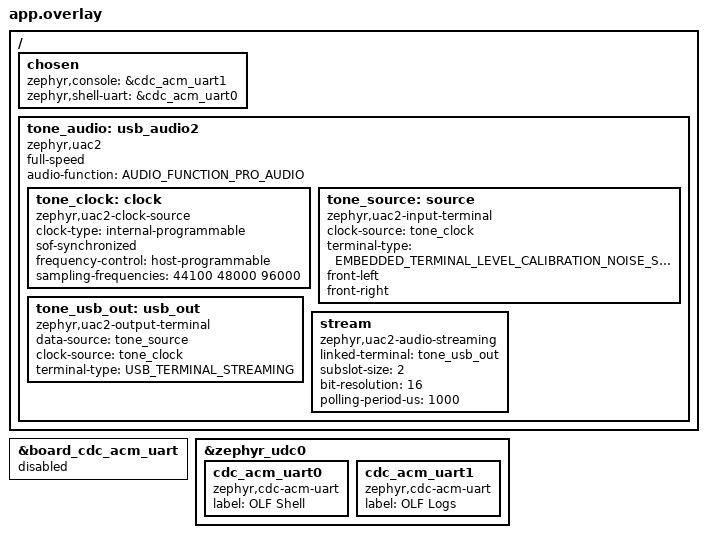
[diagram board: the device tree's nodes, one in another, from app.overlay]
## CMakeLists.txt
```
cmake_minimum_required(VERSION 3.20.0)
find_package(Zephyr REQUIRED HINTS $ENV{ZEPHYR_BASE})
project(nrf_multi_cdc_usb_next)
include(cmake/nrf52840_iso_in.cmake)
include(cmake/uac2_formats.cmake)
target_sources(app PRIVATE src/main.c src/gpio_app.c src/tone.c src/tone_usb.c)
include(cmake/tools_disk.cmake)
```

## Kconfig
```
mainmenu "OLFs Signal Generator"

source "Kconfig.zephyr"
```

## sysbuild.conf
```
# Use the original Nordic Open Bootloader; application-only sysbuild.
SB_CONFIG_BOOTLOADER_MCUBOOT=n
```

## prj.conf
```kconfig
CONFIG_SERIAL=y
CONFIG_BOOTLOADER_MCUBOOT=n
CONFIG_UART_INTERRUPT_DRIVEN=y
CONFIG_CONSOLE=y
CONFIG_UART_CONSOLE=y
CONFIG_PRINTK=y
CONFIG_SHELL=y
CONFIG_SHELL_BACKEND_SERIAL=y
CONFIG_SHELL_BACKEND_SERIAL_CHECK_DTR=y
CONFIG_LOG=y
CONFIG_LOG_DEFAULT_LEVEL=3
CONFIG_LOG_BACKEND_UART=y
CONFIG_USB_DEVICE_STACK=n
CONFIG_USB_DEVICE_STACK_NEXT=y
CONFIG_UART_LINE_CTRL=y
CONFIG_USBD_CDC_ACM_CLASS=y
CONFIG_CDC_ACM_SERIAL_INITIALIZE_AT_BOOT=n
CONFIG_MAIN_STACK_SIZE=2048
CONFIG_LOG_CMDS=y
CONFIG_LOG_RUNTIME_FILTERING=y
CONFIG_GPIO_LOG_LEVEL_DBG=y
CONFIG_GPIO=y
CONFIG_SHELL_HISTORY=y
CONFIG_SHELL_HISTORY_BUFFER=512
CONFIG_USBD_AUDIO2_CLASS=y
CONFIG_SHELL_LOG_BACKEND=n
CONFIG_SYSTEM_WORKQUEUE_STACK_SIZE=2048
CONFIG_USBD_THREAD_STACK_SIZE=2048
CONFIG_USBD_MSC_CLASS=y
```

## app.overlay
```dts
#include <dt-bindings/usb/audio.h>

/ {
    chosen {
        zephyr,console = &cdc_acm_uart1;
        zephyr,shell-uart = &cdc_acm_uart0;
    };

    tone_audio: usb_audio2 {
        compatible = "zephyr,uac2";
        status = "okay";
        full-speed;
        audio-function = <AUDIO_FUNCTION_PRO_AUDIO>;

        tone_clock: clock {
            compatible = "zephyr,uac2-clock-source";
            clock-type = "internal-programmable";
            sof-synchronized;
            frequency-control = "host-programmable";
            sampling-frequencies = <44100 48000 96000>;
        };

        tone_source: source {
            compatible = "zephyr,uac2-input-terminal";
            clock-source = <&tone_clock>;
            terminal-type = <EMBEDDED_TERMINAL_LEVEL_CALIBRATION_NOISE_SOURCE>;
            front-left;
            front-right;
        };

        tone_usb_out: usb_out {
            compatible = "zephyr,uac2-output-terminal";
            data-source = <&tone_source>;
            clock-source = <&tone_clock>;
            terminal-type = <USB_TERMINAL_STREAMING>;
        };

        stream {
            compatible = "zephyr,uac2-audio-streaming";
            linked-terminal = <&tone_usb_out>;
            /* Base alternate 1; project extension adds 24-bit alternate 2. */
            subslot-size = <2>;
            bit-resolution = <16>;
            polling-period-us = <1000>;
        };
    };
};

/* The board supplies a fourth CDC instance by default. */
&board_cdc_acm_uart {
    status = "disabled";
};

&zephyr_udc0 {
    status = "okay";

    cdc_acm_uart0: cdc_acm_uart0 {
        compatible = "zephyr,cdc-acm-uart";
        label = "OLF Shell";
    };

    cdc_acm_uart1: cdc_acm_uart1 {
        compatible = "zephyr,cdc-acm-uart";
        label = "OLF Logs";
    };
};
```

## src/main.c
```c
/* SPDX-License-Identifier: Apache-2.0 */
#include <zephyr/kernel.h>
#include <zephyr/device.h>
#include <zephyr/drivers/uart.h>
#include <zephyr/usb/usbd.h>
#include <zephyr/usb/usb_ch9.h>
#include "tone.h"
#include "tools_disk.h"
#include <zephyr/sys/util.h>
#include <zephyr/logging/log.h>
#include <errno.h>

LOG_MODULE_REGISTER(multi_cdc, LOG_LEVEL_INF);

/* USB identity for OLFs Signal Generator. */
#define DEV_VID 0x16d0
#define DEV_PID 0x1471

USBD_DEVICE_DEFINE(multi_cdc_usbd, DEVICE_DT_GET(DT_NODELABEL(zephyr_udc0)),
                   DEV_VID, DEV_PID);
USBD_DESC_LANG_DEFINE(usb_lang);
USBD_DESC_MANUFACTURER_DEFINE(usb_manufacturer, "eisenzelt.de");
USBD_DESC_PRODUCT_DEFINE(usb_product, "OLFs Signal Generator");
USBD_DESC_SERIAL_NUMBER_DEFINE(usb_serial);
USBD_DESC_CONFIG_DEFINE(fs_cfg_desc, "Audio + Shell + Logs + Tools");
USBD_CONFIGURATION_DEFINE(fs_cfg, 0, 50, &fs_cfg_desc);

static int setup_usb(void)
{
    int err;
    err = usbd_add_descriptor(&multi_cdc_usbd, &usb_lang);
    if (err) return err;
    err = usbd_add_descriptor(&multi_cdc_usbd, &usb_manufacturer);
    if (err) return err;
    err = usbd_add_descriptor(&multi_cdc_usbd, &usb_product);
    if (err) return err;
    err = usbd_add_descriptor(&multi_cdc_usbd, &usb_serial);
    if (err) return err;
    err = usbd_add_configuration(&multi_cdc_usbd, USBD_SPEED_FS, &fs_cfg);
    if (err) return err;
    /* Register two CDC ports, UAC2 audio and the read-only tools disk. */
    err = usbd_register_all_classes(&multi_cdc_usbd, USBD_SPEED_FS, 1, NULL);
    if (err) return err;
    usbd_device_set_code_triple(&multi_cdc_usbd, USBD_SPEED_FS,
                                USB_BCC_MISCELLANEOUS, 0x02, 0x01);
    err = usbd_init(&multi_cdc_usbd);
    if (err) return err;
    return usbd_enable(&multi_cdc_usbd);
}

int main(void)
{
    int err;
    err = tools_disk_init();
    if (err) {
        return err;
    }
    err = tone_usb_init();
    if (err) {
        return err;
    }

    err = setup_usb();
    if (err) {
        /* CDC console may not be operational yet: inspect return code in debugger. */
        return err;
    }
    printk("USB initialized: audio / shell / logs / tools drive\n");
    LOG_INF("USB audio generator ready: 44100/48000/96000 Hz (default %u Hz), 16/24-bit stereo", TONE_DEFAULT_SAMPLE_RATE);
    while (true) {
        k_sleep(K_SECONDS(5));
    }
    return 0;
}
```

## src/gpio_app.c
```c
/* SPDX-License-Identifier: Apache-2.0 */
#include <zephyr/drivers/gpio.h>
#include <zephyr/logging/log.h>
#include <zephyr/shell/shell.h>
#include <errno.h>
#include <string.h>

LOG_MODULE_REGISTER(gpio_app, LOG_LEVEL_DBG);

static const struct gpio_dt_spec led = GPIO_DT_SPEC_GET(DT_ALIAS(led0), gpios);

static int cmd_gpio_app_led(const struct shell *sh, size_t argc, char **argv)
{
    int err;
    int active;

    ARG_UNUSED(argc);
    if (strcmp(argv[1], "on") == 0) {
        active = 1;
    } else if (strcmp(argv[1], "off") == 0) {
        active = 0;
    } else {
        shell_error(sh, "Use: gpio_app led on|off");
        return -EINVAL;
    }

    if (!gpio_is_ready_dt(&led)) {
        LOG_ERR("LED GPIO device is not ready");
        shell_error(sh, "LED GPIO device is not ready");
        return -ENODEV;
    }

    /* Configure directly to the requested logical state, respecting active-low. */
    err = gpio_pin_configure_dt(&led, active ? GPIO_OUTPUT_ACTIVE : GPIO_OUTPUT_INACTIVE);
    if (err < 0) {
        LOG_ERR("LED configuration failed: %d", err);
        shell_error(sh, "LED configuration failed: %d", err);
        return err;
    }

    LOG_DBG("%s pin %u: LED %s (logical %d)",
            led.port->name, led.pin, active ? "on" : "off", active);
    shell_print(sh, "LED %s", active ? "on" : "off");
    return 0;
}

SHELL_STATIC_SUBCMD_SET_CREATE(gpio_app_commands,
    SHELL_CMD_ARG(led, NULL, "Set green LED: on|off", cmd_gpio_app_led, 2, 0),
    SHELL_SUBCMD_SET_END
);

SHELL_CMD_REGISTER(gpio_app, &gpio_app_commands, "Application GPIO controls", NULL);
```

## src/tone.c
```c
/* SPDX-License-Identifier: Apache-2.0 */
#include "tone.h"

static const int32_t sine_table[1025] = {
    0, 51472, 102941, 154407, 205867, 257319, 308761, 360192,
    411609, 463011, 514396, 565761, 617104, 668425, 719720, 770988,
    822227, 873435, 924611, 975751, 1026855, 1077920, 1128945, 1179927,
    1230864, 1281756, 1332599, 1383391, 1434132, 1484819, 1535450, 1586023,
    1636536, 1686988, 1737376, 1787699, 1837954, 1888140, 1938256, 1988298,
    2038265, 2088156, 2137968, 2187699, 2237349, 2286913, 2336392, 2385783,
    2435084, 2484293, 2533409, 2582430, 2631353, 2680177, 2728900, 2777521,
    2826037, 2874446, 2922747, 2970939, 3019018, 3066984, 3114834, 3162567,
    3210181, 3257674, 3305044, 3352290, 3399410, 3446402, 3493264, 3539994,
    3586592, 3633054, 3679379, 3725566, 3771613, 3817517, 3863278, 3908894,
    3954362, 3999681, 4044850, 4089867, 4134729, 4179436, 4223986, 4268376,
    4312606, 4356673, 4400577, 4444314, 4487885, 4531286, 4574517, 4617576,
    4660460, 4703170, 4745702, 4788055, 4830229, 4872220, 4914028, 4955651,
    4997087, 5038336, 5079394, 5120261, 5160936, 5201416, 5241701, 5281788,
    5321676, 5361364, 5400850, 5440132, 5479210, 5518082, 5556746, 5595200,
    5633444, 5671476, 5709294, 5746898, 5784285, 5821454, 5858404, 5895133,
    5931641, 5967925, 6003985, 6039818, 6075424, 6110801, 6145949, 6180865,
    6215548, 6249997, 6284211, 6318188, 6351927, 6385428, 6418687, 6451706,
    6484481, 6517012, 6549298, 6581337, 6613128, 6644671, 6675963, 6707004,
    6737792, 6768327, 6798607, 6828631, 6858398, 6887906, 6917156, 6946144,
    6974872, 7003337, 7031538, 7059474, 7087145, 7114548, 7141684, 7168551,
    7195148, 7221474, 7247529, 7273310, 7298818, 7324051, 7349008, 7373688,
    7398091, 7422215, 7446060, 7469624, 7492908, 7515909, 7538627, 7561061,
    7583211, 7605075, 7626653, 7647944, 7668946, 7689660, 7710085, 7730219,
    7750062, 7769614, 7788873, 7807838, 7826510, 7844887, 7862969, 7880754,
    7898243, 7915435, 7932328, 7948923, 7965219, 7981214, 7996910, 8012304,
    8027396, 8042187, 8056674, 8070858, 8084739, 8098315, 8111586, 8124551,
    8137211, 8149564, 8161611, 8173350, 8184782, 8195905, 8206720, 8217226,
    8227422, 8237309, 8246886, 8256152, 8265107, 8273751, 8282084, 8290104,
    8297813, 8305209, 8312293, 8319063, 8325521, 8331665, 8337495, 8343011,
    8348214, 8353102, 8357675, 8361934, 8365878, 8369507, 8372821, 8375819,
    8378503, 8380870, 8382923, 8384659, 8386081, 8387186, 8387975, 8388449,
    8388607, 8388449, 8387975, 8387186, 8386081, 8384659, 8382923, 8380870,
    8378503, 8375819, 8372821, 8369507, 8365878, 8361934, 8357675, 8353102,
    8348214, 8343011, 8337495, 8331665, 8325521, 8319063, 8312293, 8305209,
    8297813, 8290104, 8282084, 8273751, 8265107, 8256152, 8246886, 8237309,
    8227422, 8217226, 8206720, 8195905, 8184782, 8173350, 8161611, 8149564,
    8137211, 8124551, 8111586, 8098315, 8084739, 8070858, 8056674, 8042187,
    8027396, 8012304, 7996910, 7981214, 7965219, 7948923, 7932328, 7915435,
    7898243, 7880754, 7862969, 7844887, 7826510, 7807838, 7788873, 7769614,
    7750062, 7730219, 7710085, 7689660, 7668946, 7647944, 7626653, 7605075,
    7583211, 7561061, 7538627, 7515909, 7492908, 7469624, 7446060, 7422215,
    7398091, 7373688, 7349008, 7324051, 7298818, 7273310, 7247529, 7221474,
    7195148, 7168551, 7141684, 7114548, 7087145, 7059474, 7031538, 7003337,
    6974872, 6946144, 6917156, 6887906, 6858398, 6828631, 6798607, 6768327,
    6737792, 6707004, 6675963, 6644671, 6613128, 6581337, 6549298, 6517012,
    6484481, 6451706, 6418687, 6385428, 6351927, 6318188, 6284211, 6249997,
    6215548, 6180865, 6145949, 6110801, 6075424, 6039818, 6003985, 5967925,
    5931641, 5895133, 5858404, 5821454, 5784285, 5746898, 5709294, 5671476,
    5633444, 5595200, 5556746, 5518082, 5479210, 5440132, 5400850, 5361364,
    5321676, 5281788, 5241701, 5201416, 5160936, 5120261, 5079394, 5038336,
    4997087, 4955651, 4914028, 4872220, 4830229, 4788055, 4745702, 4703170,
    4660460, 4617576, 4574517, 4531286, 4487885, 4444314, 4400577, 4356673,
    4312606, 4268376, 4223986, 4179436, 4134729, 4089867, 4044850, 3999681,
    3954362, 3908894, 3863278, 3817517, 3771613, 3725566, 3679379, 3633054,
    3586592, 3539994, 3493264, 3446402, 3399410, 3352290, 3305044, 3257674,
    3210181, 3162567, 3114834, 3066984, 3019018, 2970939, 2922747, 2874446,
    2826037, 2777521, 2728900, 2680177, 2631353, 2582430, 2533409, 2484293,
    2435084, 2385783, 2336392, 2286913, 2237349, 2187699, 2137968, 2088156,
    2038265, 1988298, 1938256, 1888140, 1837954, 1787699, 1737376, 1686988,
    1636536, 1586023, 1535450, 1484819, 1434132, 1383391, 1332599, 1281756,
    1230864, 1179927, 1128945, 1077920, 1026855, 975751, 924611, 873435,
    822227, 770988, 719720, 668425, 617104, 565761, 514396, 463011,
    411609, 360192, 308761, 257319, 205867, 154407, 102941, 51472,
    0, -51472, -102941, -154407, -205867, -257319, -308761, -360192,
    -411609, -463011, -514396, -565761, -617104, -668425, -719720, -770988,
    -822227, -873435, -924611, -975751, -1026855, -1077920, -1128945, -1179927,
    -1230864, -1281756, -1332599, -1383391, -1434132, -1484819, -1535450, -1586023,
    -1636536, -1686988, -1737376, -1787699, -1837954, -1888140, -1938256, -1988298,
    -2038265, -2088156, -2137968, -2187699, -2237349, -2286913, -2336392, -2385783,
    -2435084, -2484293, -2533409, -2582430, -2631353, -2680177, -2728900, -2777521,
    -2826037, -2874446, -2922747, -2970939, -3019018, -3066984, -3114834, -3162567,
    -3210181, -3257674, -3305044, -3352290, -3399410, -3446402, -3493264, -3539994,
    -3586592, -3633054, -3679379, -3725566, -3771613, -3817517, -3863278, -3908894,
    -3954362, -3999681, -4044850, -4089867, -4134729, -4179436, -4223986, -4268376,
    -4312606, -4356673, -4400577, -4444314, -4487885, -4531286, -4574517, -4617576,
    -4660460, -4703170, -4745702, -4788055, -4830229, -4872220, -4914028, -4955651,
    -4997087, -5038336, -5079394, -5120261, -5160936, -5201416, -5241701, -5281788,
    -5321676, -5361364, -5400850, -5440132, -5479210, -5518082, -5556746, -5595200,
    -5633444, -5671476, -5709294, -5746898, -5784285, -5821454, -5858404, -5895133,
    -5931641, -5967925, -6003985, -6039818, -6075424, -6110801, -6145949, -6180865,
    -6215548, -6249997, -6284211, -6318188, -6351927, -6385428, -6418687, -6451706,
    -6484481, -6517012, -6549298, -6581337, -6613128, -6644671, -6675963, -6707004,
    -6737792, -6768327, -6798607, -6828631, -6858398, -6887906, -6917156, -6946144,
    -6974872, -7003337, -7031538, -7059474, -7087145, -7114548, -7141684, -7168551,
    -7195148, -7221474, -7247529, -7273310, -7298818, -7324051, -7349008, -7373688,
    -7398091, -7422215, -7446060, -7469624, -7492908, -7515909, -7538627, -7561061,
    -7583211, -7605075, -7626653, -7647944, -7668946, -7689660, -7710085, -7730219,
    -7750062, -7769614, -7788873, -7807838, -7826510, -7844887, -7862969, -7880754,
    -7898243, -7915435, -7932328, -7948923, -7965219, -7981214, -7996910, -8012304,
    -8027396, -8042187, -8056674, -8070858, -8084739, -8098315, -8111586, -8124551,
    -8137211, -8149564, -8161611, -8173350, -8184782, -8195905, -8206720, -8217226,
    -8227422, -8237309, -8246886, -8256152, -8265107, -8273751, -8282084, -8290104,
    -8297813, -8305209, -8312293, -8319063, -8325521, -8331665, -8337495, -8343011,
    -8348214, -8353102, -8357675, -8361934, -8365878, -8369507, -8372821, -8375819,
    -8378503, -8380870, -8382923, -8384659, -8386081, -8387186, -8387975, -8388449,
    -8388607, -8388449, -8387975, -8387186, -8386081, -8384659, -8382923, -8380870,
    -8378503, -8375819, -8372821, -8369507, -8365878, -8361934, -8357675, -8353102,
    -8348214, -8343011, -8337495, -8331665, -8325521, -8319063, -8312293, -8305209,
    -8297813, -8290104, -8282084, -8273751, -8265107, -8256152, -8246886, -8237309,
    -8227422, -8217226, -8206720, -8195905, -8184782, -8173350, -8161611, -8149564,
    -8137211, -8124551, -8111586, -8098315, -8084739, -8070858, -8056674, -8042187,
    -8027396, -8012304, -7996910, -7981214, -7965219, -7948923, -7932328, -7915435,
    -7898243, -7880754, -7862969, -7844887, -7826510, -7807838, -7788873, -7769614,
    -7750062, -7730219, -7710085, -7689660, -7668946, -7647944, -7626653, -7605075,
    -7583211, -7561061, -7538627, -7515909, -7492908, -7469624, -7446060, -7422215,
    -7398091, -7373688, -7349008, -7324051, -7298818, -7273310, -7247529, -7221474,
    -7195148, -7168551, -7141684, -7114548, -7087145, -7059474, -7031538, -7003337,
    -6974872, -6946144, -6917156, -6887906, -6858398, -6828631, -6798607, -6768327,
    -6737792, -6707004, -6675963, -6644671, -6613128, -6581337, -6549298, -6517012,
    -6484481, -6451706, -6418687, -6385428, -6351927, -6318188, -6284211, -6249997,
    -6215548, -6180865, -6145949, -6110801, -6075424, -6039818, -6003985, -5967925,
    -5931641, -5895133, -5858404, -5821454, -5784285, -5746898, -5709294, -5671476,
    -5633444, -5595200, -5556746, -5518082, -5479210, -5440132, -5400850, -5361364,
    -5321676, -5281788, -5241701, -5201416, -5160936, -5120261, -5079394, -5038336,
    -4997087, -4955651, -4914028, -4872220, -4830229, -4788055, -4745702, -4703170,
    -4660460, -4617576, -4574517, -4531286, -4487885, -4444314, -4400577, -4356673,
    -4312606, -4268376, -4223986, -4179436, -4134729, -4089867, -4044850, -3999681,
    -3954362, -3908894, -3863278, -3817517, -3771613, -3725566, -3679379, -3633054,
    -3586592, -3539994, -3493264, -3446402, -3399410, -3352290, -3305044, -3257674,
    -3210181, -3162567, -3114834, -3066984, -3019018, -2970939, -2922747, -2874446,
    -2826037, -2777521, -2728900, -2680177, -2631353, -2582430, -2533409, -2484293,
    -2435084, -2385783, -2336392, -2286913, -2237349, -2187699, -2137968, -2088156,
    -2038265, -1988298, -1938256, -1888140, -1837954, -1787699, -1737376, -1686988,
    -1636536, -1586023, -1535450, -1484819, -1434132, -1383391, -1332599, -1281756,
    -1230864, -1179927, -1128945, -1077920, -1026855, -975751, -924611, -873435,
    -822227, -770988, -719720, -668425, -617104, -565761, -514396, -463011,
    -411609, -360192, -308761, -257319, -205867, -154407, -102941, -51472,
    0,
};

static void tone_render_stride(struct tone_state *state, const struct tone_settings *settings,
                               uint32_t sample_rate, int32_t *samples, size_t count, size_t stride)
{
    uint32_t step = (uint32_t)(((uint64_t)settings->frequency << 32) / sample_rate);

    for (size_t i = 0; i < count; ++i) {
        uint32_t phase = state->phase;
        int32_t sample;

        switch (settings->wave) {
        case TONE_TRIANGLE: {
            uint32_t folded = (phase & 0x80000000U) ? UINT32_MAX - phase : phase;
            sample = (int32_t)(((uint64_t)folded * 16777214U) >> 31) - 8388607;
            break;
        }
        case TONE_SQUARE:
            sample = (phase & 0x80000000U) ? -8388607 : 8388607;
            break;
        case TONE_SINE:
        default: {
            uint32_t idx = phase >> 22;
            int32_t fraction = (int32_t)((phase >> 6) & 0xffffU);
            int32_t delta = (int32_t)sine_table[idx + 1] - sine_table[idx];
            sample = sine_table[idx] + (int32_t)((int64_t)delta * fraction / 65536);
            break;
        }
        }
        samples[i * stride] = settings->running ? (int32_t)((int64_t)sample * settings->amplitude / 100) : 0;
        state->phase += step;
    }
}

void tone_render(struct tone_state *state, const struct tone_settings *settings, uint32_t sample_rate,
                 int32_t *samples, size_t count)
{
    tone_render_stride(state, settings, sample_rate, samples, count, 1);
}

void tone_render_stereo(struct tone_state state[TONE_CHANNELS],
                        const struct tone_stereo_settings *settings, uint32_t sample_rate,
                        int32_t *samples, size_t frames)
{
    tone_render_stride(&state[0], &settings->channel[0], sample_rate, samples, frames, 2);
    if (settings->linked) {
        for (size_t i = 0; i < frames; ++i) {
            samples[2 * i + 1] = samples[2 * i];
        }
        state[1] = state[0];
    } else {
        tone_render_stride(&state[1], &settings->channel[1], sample_rate, samples + 1, frames, 2);
    }
}

size_t tone_next_frames(struct tone_pacing *pacing, uint32_t sample_rate)
{
    if (pacing->rate != sample_rate) {
        pacing->rate = sample_rate;
        pacing->remainder = 0;
    }
    pacing->remainder += sample_rate;
    size_t frames = pacing->remainder / 1000U;
    pacing->remainder %= 1000U;
    return frames;
}

void tone_pack_pcm24(uint8_t *destination, const int32_t *samples, size_t count)
{
    for (size_t i = 0; i < count; ++i) {
        uint32_t value = (uint32_t)samples[i];
        destination[3 * i] = (uint8_t)value;
        destination[3 * i + 1] = (uint8_t)(value >> 8);
        destination[3 * i + 2] = (uint8_t)(value >> 16);
    }
}

void tone_pack_pcm16(uint8_t *destination, const int32_t *samples, size_t count)
{
    for (size_t i = 0; i < count; ++i) {
        /* Keep the upper 16 bits of the signed 24-bit two's-complement sample. */
        uint32_t value = (uint32_t)samples[i];
        destination[2 * i] = (uint8_t)(value >> 8);
        destination[2 * i + 1] = (uint8_t)(value >> 16);
    }
}
```

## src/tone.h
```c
/* SPDX-License-Identifier: Apache-2.0 */
#ifndef OLF_TONE_H
#define OLF_TONE_H

#include <stdbool.h>
#include <stddef.h>
#include <stdint.h>

#define TONE_DEFAULT_SAMPLE_RATE 96000U
#define TONE_MAX_SAMPLE_RATE 96000U
#define TONE_SAMPLE_BYTES 3U
#define TONE_CHANNELS 2U
#define TONE_FULL_SCALE 8388607

enum tone_wave { TONE_SINE, TONE_TRIANGLE, TONE_SQUARE };

struct tone_settings {
    enum tone_wave wave;
    uint32_t frequency;
    uint32_t amplitude; /* Peak amplitude in percent of signed full scale. */
    bool running;
};

struct tone_state { uint32_t phase; };

/* Fractional samples/ms accumulator; reset automatically on rate changes. */
struct tone_pacing { uint32_t rate; uint32_t remainder; };
size_t tone_next_frames(struct tone_pacing *pacing, uint32_t sample_rate);

struct tone_stereo_settings {
    struct tone_settings channel[TONE_CHANNELS]; /* left, right */
    bool linked;
};

/* Interleaved L/R frames; linked mode uses left settings and phase for both. */
void tone_render_stereo(struct tone_state state[TONE_CHANNELS],
                        const struct tone_stereo_settings *settings, uint32_t sample_rate,
                        int32_t *samples, size_t frames);

/* Samples are signed 24-bit values stored in int32_t.
 * Phase is preserved across packet boundaries and settings changes. */
void tone_render(struct tone_state *state, const struct tone_settings *settings, uint32_t sample_rate,
                 int32_t *samples, size_t count);

/* Packed signed 24-bit little-endian USB PCM (three bytes per sample). */
void tone_pack_pcm24(uint8_t *destination, const int32_t *samples, size_t count);
/* Quantize signed 24-bit generator samples to packed signed 16-bit PCM. */
void tone_pack_pcm16(uint8_t *destination, const int32_t *samples, size_t count);

int tone_usb_init(void);

#endif
```

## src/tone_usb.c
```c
/* SPDX-License-Identifier: Apache-2.0 */
#include "tone.h"

#include <zephyr/kernel.h>
#include <zephyr/logging/log.h>
#include <zephyr/shell/shell.h>
#include <zephyr/sys/atomic.h>
#include <zephyr/usb/usbd.h>
#include <zephyr/usb/class/usbd_uac2.h>
#include <errno.h>
#include <stdlib.h>
#include <string.h>

LOG_MODULE_REGISTER(generator, LOG_LEVEL_INF);

#define MAX_FRAME_SAMPLES DIV_ROUND_UP(TONE_MAX_SAMPLE_RATE, 1000U)
#define FRAME_BYTES (MAX_FRAME_SAMPLES * TONE_CHANNELS * TONE_SAMPLE_BYTES)
#define OUTPUT_TERMINAL UAC2_ENTITY_ID(DT_NODELABEL(tone_usb_out))

BUILD_ASSERT(TONE_MAX_SAMPLE_RATE == DT_PROP_BY_IDX(DT_NODELABEL(tone_clock), sampling_frequencies, 2),
             "Generator rate must match USB clock descriptor");
BUILD_ASSERT(FRAME_BYTES <= 1023U, "Stereo PCM packet exceeds full-speed ISO maximum");

K_MEM_SLAB_DEFINE_STATIC(audio_slab, ROUND_UP(FRAME_BYTES, UDC_BUF_GRANULARITY),
                         4, UDC_BUF_ALIGN);

static struct k_spinlock settings_lock;
static struct tone_stereo_settings settings = {
    .channel = {
        { .wave = TONE_SINE, .frequency = 1000, .amplitude = 25, .running = false },
        { .wave = TONE_SINE, .frequency = 1000, .amplitude = 25, .running = false },
    },
    .linked = true,
};
/* Only the serialized USB SOF callback touches oscillator phase. */
static struct tone_state oscillator[TONE_CHANNELS];
static struct tone_pacing pacing;
static atomic_t sample_rate = ATOMIC_INIT(TONE_DEFAULT_SAMPLE_RATE);
static atomic_t sample_bytes = ATOMIC_INIT(2);
static atomic_t streaming;
static atomic_t packets;
static atomic_t dropped;

static const char *const wave_names[] = { "sine", "triangle", "square" };

/* Called by the project-local UAC2 class before the terminal state callback. */
void olf_audio_format_update(uint8_t alternate)
{
    if (alternate == 1 || alternate == 2) {
        unsigned int bytes = alternate == 1 ? 2U : 3U;
        atomic_set(&sample_bytes, bytes);
        LOG_INF("USB format selected by host: %u-bit", bytes * 8U);
    }
}

static struct tone_stereo_settings get_settings(void)
{
    k_spinlock_key_t key = k_spin_lock(&settings_lock);
    struct tone_stereo_settings copy = settings;

    k_spin_unlock(&settings_lock, key);
    return copy;
}

static void audio_release(const struct device *dev, uint8_t terminal,
                          void *buf, void *user_data)
{
    ARG_UNUSED(dev);
    ARG_UNUSED(terminal);
    ARG_UNUSED(user_data);
    k_mem_slab_free(&audio_slab, buf);
}

static void audio_terminal(const struct device *dev, uint8_t terminal,
                           bool enabled, bool microframes, void *user_data)
{
    ARG_UNUSED(dev);
    ARG_UNUSED(user_data);
    if (terminal == OUTPUT_TERMINAL) {
        atomic_set(&streaming, enabled && !microframes);
        LOG_INF("Host audio capture %s", enabled ? "enabled" : "disabled");
    }
}

static void audio_sof(const struct device *dev, void *user_data)
{
    ARG_UNUSED(user_data);
    if (!atomic_get(&streaming)) {
        return;
    }

    uint32_t rate = (uint32_t)atomic_get(&sample_rate);
    unsigned int bytes = (unsigned int)atomic_get(&sample_bytes);
    size_t frames = tone_next_frames(&pacing, rate);
    struct tone_stereo_settings current = get_settings();
    int32_t samples[MAX_FRAME_SAMPLES * TONE_CHANNELS];
    void *buffer;

    /* Advance phase even if this frame cannot be queued. */
    tone_render_stereo(oscillator, &current, rate, samples, frames);
    if (k_mem_slab_alloc(&audio_slab, &buffer, K_NO_WAIT)) {
        atomic_inc(&dropped);
        return;
    }
    if (bytes == 2U) {
        tone_pack_pcm16(buffer, samples, frames * TONE_CHANNELS);
    } else {
        tone_pack_pcm24(buffer, samples, frames * TONE_CHANNELS);
    }
    if (usbd_uac2_send(dev, OUTPUT_TERMINAL, buffer, frames * TONE_CHANNELS * bytes) < 0) {
        k_mem_slab_free(&audio_slab, buffer);
        atomic_inc(&dropped);
    } else {
        atomic_inc(&packets);
    }
}

static uint32_t audio_get_rate(const struct device *dev, uint8_t clock_id, void *user_data)
{
    ARG_UNUSED(dev);
    ARG_UNUSED(clock_id);
    ARG_UNUSED(user_data);
    return (uint32_t)atomic_get(&sample_rate);
}

static int audio_set_rate(const struct device *dev, uint8_t clock_id,
                          uint32_t rate, void *user_data)
{
    ARG_UNUSED(dev);
    ARG_UNUSED(user_data);
    if (clock_id != UAC2_ENTITY_ID(DT_NODELABEL(tone_clock)) ||
        (rate != 44100U && rate != 48000U && rate != 96000U)) {
        return -EINVAL;
    }
    atomic_set(&sample_rate, rate);
    LOG_INF("USB sample rate selected by host: %u Hz", rate);
    return 0;
}

static const struct uac2_ops audio_ops = {
    .sof_cb = audio_sof,
    .terminal_update_cb = audio_terminal,
    .buf_release_cb = audio_release,
    .get_sample_rate = audio_get_rate,
    .set_sample_rate = audio_set_rate,
};

int tone_usb_init(void)
{
    const struct device *dev = DEVICE_DT_GET(DT_NODELABEL(tone_audio));

    if (!device_is_ready(dev)) {
        return -ENODEV;
    }
    usbd_uac2_set_ops(dev, &audio_ops, NULL);
    return 0;
}

static int cmd_status(const struct shell *sh, size_t argc, char **argv)
{
    ARG_UNUSED(argc);
    ARG_UNUSED(argv);
    struct tone_stereo_settings current = get_settings();

    shell_print(sh, "Channels: %s", current.linked ? "linked (left master)" : "independent");
    for (size_t i = 0; i < TONE_CHANNELS; ++i) {
        const struct tone_settings *ch = &current.channel[i];
        shell_print(sh, "%s: %s, %s, %u Hz, %u%% peak amplitude",
                    i ? "right" : "left", ch->running ? "running" : "stopped",
                    wave_names[ch->wave], ch->frequency, ch->amplitude);
    }
    shell_print(sh, "USB: %u Hz / %u-bit / stereo, host capture %s",
                (unsigned int)atomic_get(&sample_rate), (unsigned int)atomic_get(&sample_bytes) * 8U,
                atomic_get(&streaming) ? "active" : "inactive");
    shell_print(sh, "Packets queued: %u, dropped: %u",
                (unsigned int)atomic_get(&packets), (unsigned int)atomic_get(&dropped));
    return 0;
}

/* Optional final argument selects a channel; omitted means both. */
static int channel_mask(const struct shell *sh, const char *name)
{
    if (!name || strcmp(name, "both") == 0) return 3;
    if (strcmp(name, "left") == 0) return 1;
    if (strcmp(name, "right") == 0) return 2;
    shell_error(sh, "Channel must be left, right or both");
    return -EINVAL;
}

static int cmd_run(const struct shell *sh, size_t argc, char **argv)
{
    int mask = channel_mask(sh, argc == 2 ? argv[1] : NULL);
    if (mask < 0) return mask;
    bool run = strcmp(argv[0], "start") == 0;
    k_spinlock_key_t key = k_spin_lock(&settings_lock);
    if (settings.linked) mask = 3;
    for (size_t i = 0; i < TONE_CHANNELS; ++i) {
        if (mask & BIT(i)) settings.channel[i].running = run;
    }
    k_spin_unlock(&settings_lock, key);
    LOG_INF("Generator %s, channel mask %d", run ? "started" : "stopped", mask);
    return cmd_status(sh, 0, NULL);
}

static int cmd_wave(const struct shell *sh, size_t argc, char **argv)
{
    int mask = channel_mask(sh, argc == 3 ? argv[2] : NULL);
    if (mask < 0) return mask;
    for (size_t wave = 0; wave < ARRAY_SIZE(wave_names); ++wave) {
        if (strcmp(argv[1], wave_names[wave]) == 0) {
            k_spinlock_key_t key = k_spin_lock(&settings_lock);
            if (settings.linked) mask = 3;
            for (size_t i = 0; i < TONE_CHANNELS; ++i) {
                if (mask & BIT(i)) settings.channel[i].wave = (enum tone_wave)wave;
            }
            k_spin_unlock(&settings_lock, key);
            LOG_INF("Waveform: %s, channel mask %d", wave_names[wave], mask);
            return cmd_status(sh, 0, NULL);
        }
    }
    shell_error(sh, "Use: gen wave sine|triangle|square [left|right|both]");
    return -EINVAL;
}

static int cmd_number(const struct shell *sh, size_t argc, char **argv)
{
    int mask = channel_mask(sh, argc == 3 ? argv[2] : NULL);
    if (mask < 0) return mask;
    bool frequency = strcmp(argv[0], "freq") == 0;
    unsigned long min = frequency ? 1 : 0;
    unsigned long max = frequency ? 20000 : 100;
    char *end;

    errno = 0;
    unsigned long value = strtoul(argv[1], &end, 10);
    if (argv[1][0] < '0' || argv[1][0] > '9' || *end || errno == ERANGE ||
        value < min || value > max) {
        shell_error(sh, "%s requires an integer from %lu to %lu", argv[0], min, max);
        return -EINVAL;
    }
    k_spinlock_key_t key = k_spin_lock(&settings_lock);
    if (settings.linked) mask = 3;
    for (size_t i = 0; i < TONE_CHANNELS; ++i) {
        if (!(mask & BIT(i))) continue;
        if (frequency) settings.channel[i].frequency = (uint32_t)value;
        else settings.channel[i].amplitude = (uint32_t)value;
    }
    k_spin_unlock(&settings_lock, key);
    LOG_INF("%s: %lu, channel mask %d", frequency ? "Frequency (Hz)" : "Amplitude (%)", value, mask);
    return cmd_status(sh, 0, NULL);
}

static int cmd_link(const struct shell *sh, size_t argc, char **argv)
{
    ARG_UNUSED(argc);
    bool link;
    if (strcmp(argv[1], "on") == 0) link = true;
    else if (strcmp(argv[1], "off") == 0) link = false;
    else {
        shell_error(sh, "Use: gen link on|off");
        return -EINVAL;
    }
    k_spinlock_key_t key = k_spin_lock(&settings_lock);
    settings.linked = link;
    if (link) settings.channel[1] = settings.channel[0];
    k_spin_unlock(&settings_lock, key);
    LOG_INF("Channels %s", link ? "linked (left master)" : "independent");
    return cmd_status(sh, 0, NULL);
}

SHELL_STATIC_SUBCMD_SET_CREATE(generator_commands,
    SHELL_CMD_ARG(status, NULL, "Show generator and USB stream status", cmd_status, 1, 0),
    SHELL_CMD_ARG(start, NULL, "Start [left|right|both]", cmd_run, 1, 1),
    SHELL_CMD_ARG(stop, NULL, "Stop [left|right|both]", cmd_run, 1, 1),
    SHELL_CMD_ARG(wave, NULL, "sine|triangle|square [left|right|both]", cmd_wave, 2, 1),
    SHELL_CMD_ARG(freq, NULL, "1..20000 Hz [left|right|both]", cmd_number, 2, 1),
    SHELL_CMD_ARG(amp, NULL, "0..100 percent [left|right|both]", cmd_number, 2, 1),
    SHELL_CMD_ARG(link, NULL, "Couple channels: on|off (left master)", cmd_link, 2, 0),
    SHELL_SUBCMD_SET_END
);

SHELL_CMD_REGISTER(gen, &generator_commands, "USB audio signal generator", NULL);
```

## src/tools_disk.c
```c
/* SPDX-License-Identifier: Apache-2.0 */
#include "tools_disk.h"
#include <zephyr/storage/disk_access.h>
#include <zephyr/usb/class/usbd_msc.h>
#include <errno.h>
#include <string.h>

#define DISK_NAME "OLFTOOLS"
#define SECTOR_SIZE 512U
#define SECTORS 1024U

extern const uint8_t olf_tools_disk_start[];
extern const uint8_t olf_tools_disk_end[];

USBD_DEFINE_MSC_LUN(olf_tools, DISK_NAME, "OLF", "Console Tools", "1.00");

static int disk_init(struct disk_info *disk) { ARG_UNUSED(disk); return 0; }
static int disk_status(struct disk_info *disk)
{
    ARG_UNUSED(disk);
    return DISK_STATUS_WR_PROTECT;
}

static int disk_read(struct disk_info *disk, uint8_t *buffer, uint32_t start, uint32_t count)
{
    ARG_UNUSED(disk);
    if (start > SECTORS || count > SECTORS - start) return -EINVAL;
    memcpy(buffer, olf_tools_disk_start + start * SECTOR_SIZE, count * SECTOR_SIZE);
    return 0;
}

static int disk_write(struct disk_info *disk, const uint8_t *buffer, uint32_t start, uint32_t count)
{
    ARG_UNUSED(disk); ARG_UNUSED(buffer); ARG_UNUSED(start); ARG_UNUSED(count);
    return -EROFS;
}

static int disk_ioctl(struct disk_info *disk, uint8_t command, void *buffer)
{
    ARG_UNUSED(disk);
    switch (command) {
    case DISK_IOCTL_GET_SECTOR_COUNT: *(uint32_t *)buffer = SECTORS; return 0;
    case DISK_IOCTL_GET_SECTOR_SIZE: *(uint32_t *)buffer = SECTOR_SIZE; return 0;
    case DISK_IOCTL_GET_ERASE_BLOCK_SZ: *(uint32_t *)buffer = 1; return 0;
    case DISK_IOCTL_CTRL_SYNC:
    case DISK_IOCTL_CTRL_INIT:
    case DISK_IOCTL_CTRL_DEINIT: return 0;
    default: return -EINVAL;
    }
}

static const struct disk_operations disk_ops = {
    .init = disk_init, .status = disk_status, .read = disk_read,
    .write = disk_write, .ioctl = disk_ioctl,
};
static struct disk_info tools_disk = { .name = DISK_NAME, .ops = &disk_ops };

int tools_disk_init(void)
{
    if ((size_t)(olf_tools_disk_end - olf_tools_disk_start) != SECTOR_SIZE * SECTORS) return -EINVAL;
    int err = disk_access_register(&tools_disk);
    return err ? err : disk_access_init(DISK_NAME);
}
```

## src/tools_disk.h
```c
/* SPDX-License-Identifier: Apache-2.0 */
#ifndef OLF_TOOLS_DISK_H
#define OLF_TOOLS_DISK_H
int tools_disk_init(void);
#endif
```

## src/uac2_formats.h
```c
/* SPDX-License-Identifier: Apache-2.0 */
/* Project-only extension: one full-speed, synchronous USB IN stream.
 * The DT-generated alternate 1 is 16-bit. Alternate 2 adds packed 24-bit.
 */
#undef AS_DESCRIPTORS_ARRAYS
#define AS_DESCRIPTORS_ARRAYS(node) \
    OLF_BASE_AS_DESCRIPTORS_ARRAYS(node) \
    BUILD_ASSERT(AS_IS_USB_ISO_IN(node) && AS_IS_SOF_SYNCHRONIZED(node), \
                 "Format extension requires a synchronous IN stream"); \
    BUILD_ASSERT(!UAC2_ALLOWED_AT_HIGH_SPEED(DT_PARENT(node)), "Full-speed only"); \
    BUILD_ASSERT(DT_PROP(node, subslot_size) == 2 && DT_PROP(node, bit_resolution) == 16, \
                 "Base alternate must be 16-bit PCM"); \
    AS_INTERFACE_FS_DESCRIPTOR_ARRAY(node, 2, 1) \
    static uint8_t DESCRIPTOR_NAME(as_format24_desc, node)[] = {6, CS_INTERFACE, 2, 1, 3, 24}; \
    static uint8_t DESCRIPTOR_NAME(fs_std_data_ep24, node)[] = { \
        7, USB_DESC_ENDPOINT, AS_DATA_EP_ADDR(node), AS_DATA_EP_ATTR(node), \
        U16_LE(AUDIO_STREAMING_NUM_SPATIAL_LOCATIONS(node) * 3 * AS_SAMPLES_PER_FRAME(node)), \
        AS_FS_DATA_EP_BINTERVAL(node), \
    };

#undef AS_FS_DESCRIPTORS_PTRS
#define AS_FS_DESCRIPTORS_PTRS(node) \
    OLF_BASE_AS_FS_DESCRIPTORS_PTRS(node) \
    AS_INTERFACE_FS_DESCRIPTOR_PTR(node, 2) \
    (struct usb_desc_header *)&DESCRIPTOR_NAME(as_general_desc, node), \
    (struct usb_desc_header *)&DESCRIPTOR_NAME(as_format24_desc, node), \
    (struct usb_desc_header *)&DESCRIPTOR_NAME(fs_std_data_ep24, node), \
    (struct usb_desc_header *)&DESCRIPTOR_NAME(cs_data_ep, node),

/* Five descriptor pointers are appended for alternate 2. The class's endpoint
 * lookup keeps pointing at alternate 1. Both alternates use the sole ISO-IN
 * hardware endpoint (0x88); send() only uses its address, not its packet size.
 */
#undef UAC2_DESCRIPTOR_AS_DATA_EP_INDEX
#define UAC2_DESCRIPTOR_AS_DATA_EP_INDEX(node) \
    (UAC2_DESCRIPTOR_AS_DESC_END_COUNT(node) - 5 \
     - AS_EXPLICIT_FEEDBACK_ENDPOINT_DESCRIPTOR_COUNT(node) \
     - AS_ISOCHRONOUS_DATA_ENDPOINT_DESCRIPTORS_COUNT(node))

void olf_audio_format_update(uint8_t alternate);
```
